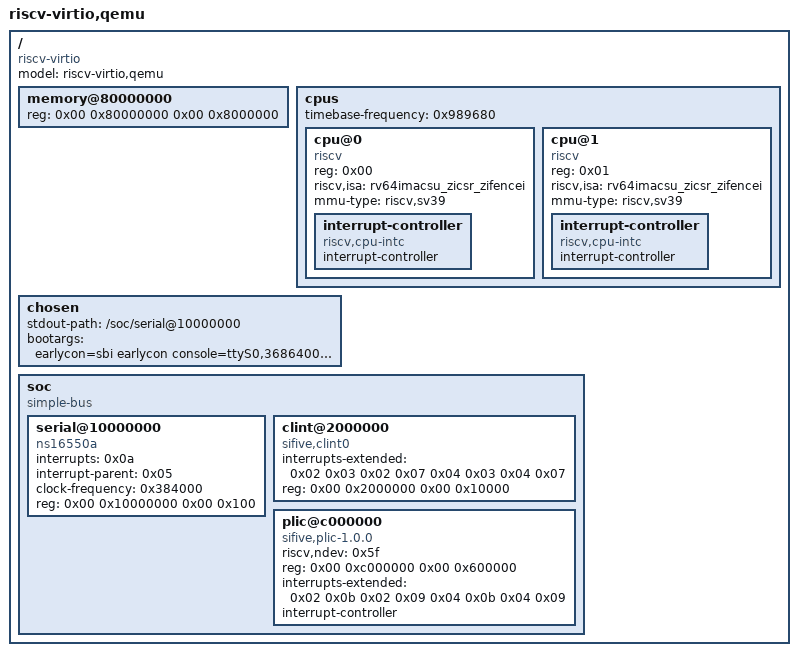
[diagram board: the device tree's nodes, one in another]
/dts-v1/;

/ {
	#address-cells = <0x02>;
	#size-cells = <0x02>;
	compatible = "riscv-virtio";
	model = "riscv-virtio,qemu";

	memory@80000000 {
		device_type = "memory";
		reg = <0x00 0x80000000 0x00 0x8000000>;
	};

	cpus {
		#address-cells = <0x01>;
		#size-cells = <0x00>;
		timebase-frequency = <0x989680>;

		cpu@0 {
			phandle = <0x01>;
			device_type = "cpu";
			reg = <0x00>;
			status = "okay";
			compatible = "riscv";
			riscv,isa = "rv64imacsu_zicsr_zifencei";
			mmu-type = "riscv,sv39";

			interrupt-controller {
				#interrupt-cells = <0x01>;
				interrupt-controller;
				compatible = "riscv,cpu-intc";
				phandle = <0x02>;
			};
		};

		cpu@1 {
			phandle = <0x03>;
			device_type = "cpu";
			reg = <0x01>;
			status = "okay";
			compatible = "riscv";
			riscv,isa = "rv64imacsu_zicsr_zifencei";
			mmu-type = "riscv,sv39";

			interrupt-controller {
				#interrupt-cells = <0x01>;
				interrupt-controller;
				compatible = "riscv,cpu-intc";
				phandle = <0x04>;
			};
		};
	};

	chosen {
		stdout-path = "/soc/serial@10000000";
		bootargs = "earlycon=sbi earlycon console=ttyS0,3686400 root=/dev/ram0 rdinit=/init";
	};

	soc {
		#address-cells = <0x02>;
		#size-cells = <0x02>;
		compatible = "simple-bus";
		ranges;

		serial@10000000 {
			interrupts = <0x0a>;
			interrupt-parent = <0x05>;
			clock-frequency = <0x384000>;
			reg = <0x00 0x10000000 0x00 0x100>;
			compatible = "ns16550a";
		};

		clint@2000000 {
			interrupts-extended = <0x02 0x03 0x02 0x07 0x04 0x03 0x04 0x07>;
			reg = <0x00 0x2000000 0x00 0x10000>;
			compatible = "sifive,clint0", "riscv,clint0";
		};

		plic@c000000 {
			phandle = <0x05>;
			riscv,ndev = <0x5f>;
			reg = <0x00 0xc000000 0x00 0x600000>;
			interrupts-extended = <0x02 0x0b 0x02 0x09 0x04 0x0b 0x04 0x09>;
			interrupt-controller;
			compatible = "sifive,plic-1.0.0", "riscv,plic0";
			#address-cells = <0x00>;
			#interrupt-cells = <0x01>;
		};
	};
};
